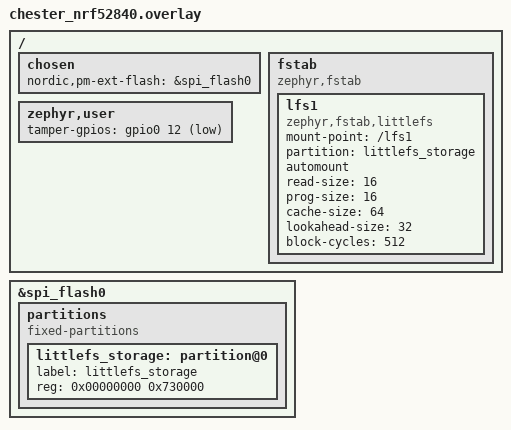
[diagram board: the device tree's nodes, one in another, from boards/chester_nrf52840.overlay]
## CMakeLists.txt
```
#
# Copyright (c) 2023 HARDWARIO a.s.
#
# SPDX-License-Identifier: LicenseRef-HARDWARIO-5-Clause
#

cmake_minimum_required(VERSION 3.20.0)

set(SHIELD ctr_k1 ctr_lte_v2 ctr_ds18b20 ctr_z)
set(ENV{FW_BUNDLE} "com.hardwario.chester.app.batterycheck.current")
set(ENV{FW_VERSION} "v2.1.0")
set(ENV{FW_NAME} "CHESTER BatteryCheck")

find_package(Zephyr REQUIRED HINTS $ENV{ZEPHYR_BASE})
project(app)

add_custom_command(
  COMMAND west gen-codec -d ../codec/cbor-decoder.yaml -e ../codec/cbor-encoder.yaml -o ../src/app_codec.h
  OUTPUT ../src/app_codec.h
  DEPENDS ../codec/cbor-decoder.yaml ../codec/cbor-encoder.yaml
)

target_sources(app PRIVATE src/app_cbor.c)
target_sources(app PRIVATE src/app_config.c)

target_sources(app PRIVATE src/app_backup.c)
target_sources(app PRIVATE src/app_tamper.c)
target_sources(app PRIVATE src/app_data.c)
target_sources(app PRIVATE src/app_handler.c)
target_sources(app PRIVATE src/app_init.c)
target_sources(app PRIVATE src/app_power.c)
target_sources(app PRIVATE src/app_sensor.c)
target_sources(app PRIVATE src/app_shell.c)
target_sources(app PRIVATE src/app_work.c)

target_sources(app PRIVATE src/main.c)

target_sources(app PRIVATE src/app_codec.h)
```

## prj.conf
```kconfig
#
# Copyright (c) 2023 HARDWARIO a.s.
#
# SPDX-License-Identifier: LicenseRef-HARDWARIO-5-Clause
#

CONFIG_ADC_NRFX_SAADC=n
CONFIG_ADC_SHELL=n

CONFIG_CTR_ACCEL=y
CONFIG_CTR_BATT=y

CONFIG_CTR_BUTTON=y
CONFIG_APP_TAMPER=y
CONFIG_CTR_BLE=n

CONFIG_CTR_BUF=y
CONFIG_CTR_CLOUD=y
CONFIG_CTR_DEFAULTS=y
CONFIG_CTR_INFO=y
CONFIG_CTR_LED=y
CONFIG_CTR_LOG=y
CONFIG_CTR_RTC=y
CONFIG_CTR_SHELL=y
CONFIG_CTR_THERM=y
CONFIG_CTR_WDOG=y
CONFIG_NEWLIB_LIBC_NANO=n
CONFIG_TINYCRYPT=y
CONFIG_TINYCRYPT_SHA256=y
CONFIG_ZCBOR=y
CONFIG_ZCBOR_STOP_ON_ERROR=y
CONFIG_ENTROPY_GENERATOR=y
CONFIG_SETTINGS_SHELL=y
CONFIG_IMG_MANAGER=y
CONFIG_BOOTLOADER_MCUBOOT=y
CONFIG_CTR_LTE_V2_GNSS=y
CONFIG_CTR_GNSS=y

# CONFIG_MCUBOOT_EXTRA_IMGTOOL_ARGS="--custom-tlv 0xff00 tralala"

CONFIG_PM_PARTITION_SIZE_SETTINGS_STORAGE=0x8000
CONFIG_PM_OVERRIDE_EXTERNAL_DRIVER_CHECK=y
CONFIG_SPI=y

CONFIG_DFU_TARGET=y
CONFIG_DFU_TARGET_STREAM=y
CONFIG_DFU_TARGET_MCUBOOT=y
CONFIG_DFU_TARGET_LOG_LEVEL_DBG=y

CONFIG_STREAM_FLASH_ERASE=y
CONFIG_STREAM_FLASH=y

# CONFIG_CTR_LTE_LINK_LOG_LEVEL_DBG=y
# CONFIG_CTR_LTE_LINK_LOG_LEVEL_INF=y
# CONFIG_CTR_LTE_LINK_LOG_LEVEL_ERR=y

CONFIG_CTR_LTE_V2_LOG_LEVEL_DBG=y
# CONFIG_CTR_LTE_V2_LOG_LEVEL_ERR=y

CONFIG_CTR_K1_LOG_LEVEL_DBG=y
# CONFIG_CTR_K1_LOG_LEVEL_ERR=y

CONFIG_ADC_TLA2021_INIT_PRIORITY=60


# Enable file system support
CONFIG_FILE_SYSTEM=y
CONFIG_FILE_SYSTEM_LITTLEFS=y
CONFIG_FILE_SYSTEM_MKFS=y
CONFIG_FILE_SYSTEM_SHELL=y
# CONFIG_FILE_SYSTEM_SHELL_TEST_COMMANDS=y
CONFIG_SETTINGS_FILE=y
CONFIG_SETTINGS_FILE_PATH="/lfs1/settings/run"
# Use external flash for littlefs file system
CONFIG_PM_PARTITION_REGION_LITTLEFS_EXTERNAL=y
```

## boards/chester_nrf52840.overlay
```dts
/*
 * Copyright (c) 2023 HARDWARIO a.s.
 *
 * SPDX-License-Identifier: LicenseRef-HARDWARIO-5-Clause
 */

/ {
	chosen {
		nordic,pm-ext-flash = &spi_flash0;
	};
};

&spi_flash0 {
	partitions {
		compatible = "fixed-partitions";
		#address-cells = <1>;
		#size-cells = <1>;

		littlefs_storage: partition@0 {
			label = "littlefs_storage";

			/*
			 * This size doesn't matter due to Nordic's partition
			 * manager; For the sake of consistency this should
			 * match the configured size
			 */
			reg = <0x00000000 0x730000>;
		};
	};
};

/ {
	fstab {
		compatible = "zephyr,fstab";
		lfs1: lfs1 {
			compatible = "zephyr,fstab,littlefs";
			mount-point = "/lfs1";
			partition = <&littlefs_storage>;
			automount;
			read-size = <16>;
			prog-size = <16>;
			cache-size = <64>;
			lookahead-size = <32>;
			block-cycles = <512>;
		};
	};
};

/ {
	zephyr,user {
		tamper-gpios = <&gpio0 12 GPIO_ACTIVE_LOW>;
	};
};
```

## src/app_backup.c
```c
#include "app_backup.h"
#include "app_data.h"
#include "app_work.h"

/* CHESTER includes */
#include <chester/drivers/ctr_z.h>

/* Zephyr includes */
#include <zephyr/device.h>
#include <zephyr/devicetree.h>
#include <zephyr/kernel.h>
#include <zephyr/logging/log.h>

/* Standard includes */
#include <errno.h>
#include <math.h>
#include <stdbool.h>

LOG_MODULE_REGISTER(app_backup, LOG_LEVEL_DBG);

#if defined(CONFIG_SHIELD_CTR_Z)

int app_backup_sample(void)
{
	int ret;

	static const struct device *dev = DEVICE_DT_GET(DT_NODELABEL(ctr_z));

	if (!device_is_ready(dev)) {
		LOG_ERR("Device not ready");
		ret = -ENODEV;
		goto error;
	}

	struct ctr_z_status status;
	ret = ctr_z_get_status(dev, &status);
	if (ret) {
		LOG_ERR("Call `ctr_z_get_status` failed: %d", ret);
		goto error;
	}

	LOG_INF("DC input connected: %d", status.dc_input_connected);

	uint16_t vdc;
	ret = ctr_z_get_vdc_mv(dev, &vdc);
	if (ret) {
		LOG_ERR("Call `ctr_z_get_vdc_mv` failed: %d", ret);
		goto error;
	}

	LOG_INF("Voltage DC input: %u mV", vdc);

	uint16_t vbat;
	ret = ctr_z_get_vbat_mv(dev, &vbat);
	if (ret) {
		LOG_ERR("Call `ctr_z_get_vbat_mv` failed: %d", ret);
		goto error;
	}

	LOG_INF("Voltage backup battery: %u mV", vbat);

	app_data_lock();
	g_app_data.backup.line_present = status.dc_input_connected;
	g_app_data.backup.line_voltage = vdc / 1000.f;
	g_app_data.backup.battery_voltage = vbat / 1000.f;
	app_data_unlock();

	return 0;

error:
	app_data_lock();
	g_app_data.backup.line_present = false;
	g_app_data.backup.line_voltage = NAN;
	g_app_data.backup.battery_voltage = NAN;
	app_data_unlock();

	return ret;
}

int app_backup_clear(void)
{
	app_data_lock();
	g_app_data.backup.event_count = 0;

	for (int i = 0; i < APP_DATA_BUTTON_COUNT; i++) {
		g_app_data.button[i].event_count = 0;
	}
	app_data_unlock();

	return 0;
}

#endif /* defined(CONFIG_SHIELD_CTR_Z) */
```

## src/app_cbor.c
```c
#include "app_cbor.h"
#include "app_data.h"
#include "app_codec.h"

/* CHESTER includes */
#include <chester/ctr_info.h>
#include <chester/ctr_lte_v2.h>
#include <chester/ctr_rtc.h>
#include <chester/ctr_buf.h>
#include <chester/ctr_cloud.h>
#include <chester/drivers/ctr_z.h>

/* Zephyr includes */
#include <zephyr/kernel.h>
#include <zephyr/logging/log.h>

#include <zcbor_common.h>
#include <zcbor_decode.h>
#include <zcbor_encode.h>

/* Standard includes */
#include <errno.h>
#include <math.h>
#include <stdbool.h>
#include <stddef.h>
#include <stdint.h>
#include <stdlib.h>

// #define CONFIG_SHIELD_CTR_Z 1

LOG_MODULE_REGISTER(app_cbor, LOG_LEVEL_DBG);

__unused static void put_sample_mul(zcbor_state_t *zs, struct app_data_analog_aggreg *sample,
				    float mul)
{
	if (isnan(sample->min)) {
		zcbor_nil_put(zs, NULL);
	} else {
		zcbor_int32_put(zs, sample->min * mul);
	}

	if (isnan(sample->max)) {
		zcbor_nil_put(zs, NULL);
	} else {
		zcbor_int32_put(zs, sample->max * mul);
	}

	if (isnan(sample->avg)) {
		zcbor_nil_put(zs, NULL);
	} else {
		zcbor_int32_put(zs, sample->avg * mul);
	}

	if (isnan(sample->mdn)) {
		zcbor_nil_put(zs, NULL);
	} else {
		zcbor_int32_put(zs, sample->mdn * mul);
	}
}

__unused static void put_sample(zcbor_state_t *zs, struct app_data_analog_aggreg *sample)
{
	put_sample_mul(zs, sample, 1.f);
}

int encode(zcbor_state_t *zs)
{
	int ret;

	zs->constant_state->stop_on_error = true;

	zcbor_map_start_encode(zs, ZCBOR_VALUE_IS_INDEFINITE_LENGTH);

	zcbor_uint32_put(zs, CODEC_KEY_E_MESSAGE);
	{
		zcbor_map_start_encode(zs, ZCBOR_VALUE_IS_INDEFINITE_LENGTH);

		zcbor_uint32_put(zs, CODEC_KEY_E_MESSAGE__SEQUENCE);
		zcbor_uint32_put(zs, g_app_data.sequence++);

		uint64_t timestamp;
		ret = ctr_rtc_get_ts(&timestamp);
		if (ret) {
			LOG_ERR("Call `ctr_rtc_get_ts` failed: %d", ret);
			return ret;
		}

		zcbor_uint32_put(zs, CODEC_KEY_E_MESSAGE__TIMESTAMP);
		zcbor_uint64_put(zs, timestamp);

		zcbor_map_end_encode(zs, ZCBOR_VALUE_IS_INDEFINITE_LENGTH);
	}

	zcbor_uint32_put(zs, CODEC_KEY_E_SYSTEM);
	{
		zcbor_map_start_encode(zs, ZCBOR_VALUE_IS_INDEFINITE_LENGTH);

		zcbor_uint32_put(zs, CODEC_KEY_E_SYSTEM__UPTIME);
		zcbor_uint64_put(zs, k_uptime_get() / 1000);

		zcbor_uint32_put(zs, CODEC_KEY_E_SYSTEM__VOLTAGE_REST);
		if (isnan(g_app_data.system_voltage_rest)) {
			zcbor_nil_put(zs, NULL);
		} else {
			zcbor_uint32_put(zs, g_app_data.system_voltage_rest);
		}

		zcbor_uint32_put(zs, CODEC_KEY_E_SYSTEM__VOLTAGE_LOAD);
		if (isnan(g_app_data.system_voltage_load)) {
			zcbor_nil_put(zs, NULL);
		} else {
			zcbor_uint32_put(zs, g_app_data.system_voltage_load);
		}

		zcbor_uint32_put(zs, CODEC_KEY_E_SYSTEM__CURRENT_LOAD);
		if (isnan(g_app_data.system_current_load)) {
			zcbor_nil_put(zs, NULL);
		} else {
			zcbor_uint32_put(zs, g_app_data.system_current_load);
		}

		char *serial_number;
		ctr_info_get_serial_number(&serial_number);

		zcbor_uint32_put(zs, CODEC_KEY_E_SYSTEM__SERIAL_NUMBER);
		zcbor_tstr_put_term(zs, serial_number);

		zcbor_map_end_encode(zs, ZCBOR_VALUE_IS_INDEFINITE_LENGTH);
	}

	zcbor_uint32_put(zs, CODEC_KEY_E_NETWORK);
	{
		zcbor_map_start_encode(zs, ZCBOR_VALUE_IS_INDEFINITE_LENGTH);

		zcbor_uint32_put(zs, CODEC_KEY_E_NETWORK__PARAMETER);
		{
			zcbor_map_start_encode(zs, ZCBOR_VALUE_IS_INDEFINITE_LENGTH);

			static struct ctr_lte_v2_conn_param conn_param;
			ret = ctr_lte_v2_get_conn_param(&conn_param);
			if (ret) {
				LOG_ERR("Call `ctr_lte_v2_state_get_conn_param` failed: %d", ret);
				return ret;
			}

			zcbor_uint32_put(zs, CODEC_KEY_E_NETWORK__PARAMETER__EEST);
			if (conn_param.valid) {
				zcbor_int32_put(zs, conn_param.eest);
			} else {
				zcbor_nil_put(zs, NULL);
			}

			zcbor_uint32_put(zs, CODEC_KEY_E_NETWORK__PARAMETER__ECL);
			if (conn_param.valid) {
				zcbor_int32_put(zs, conn_param.ecl);
			} else {
				zcbor_nil_put(zs, NULL);
			}

			zcbor_uint32_put(zs, CODEC_KEY_E_NETWORK__PARAMETER__RSRP);
			if (conn_param.valid) {
				zcbor_int32_put(zs, conn_param.rsrp);
			} else {
				zcbor_nil_put(zs, NULL);
			}

			zcbor_uint32_put(zs, CODEC_KEY_E_NETWORK__PARAMETER__RSRQ);
			if (conn_param.valid) {
				zcbor_int32_put(zs, conn_param.rsrq);
			} else {
				zcbor_nil_put(zs, NULL);
			}

			zcbor_uint32_put(zs, CODEC_KEY_E_NETWORK__PARAMETER__SNR);
			if (conn_param.valid) {
				zcbor_int32_put(zs, conn_param.snr);
			} else {
				zcbor_nil_put(zs, NULL);
			}

			zcbor_uint32_put(zs, CODEC_KEY_E_NETWORK__PARAMETER__PLMN);
			if (conn_param.valid) {
				zcbor_int32_put(zs, conn_param.plmn);
			} else {
				zcbor_nil_put(zs, NULL);
			}

			zcbor_uint32_put(zs, CODEC_KEY_E_NETWORK__PARAMETER__CID);
			if (conn_param.valid) {
				zcbor_int32_put(zs, conn_param.cid);
			} else {
				zcbor_nil_put(zs, NULL);
			}

			zcbor_uint32_put(zs, CODEC_KEY_E_NETWORK__PARAMETER__BAND);
			if (conn_param.valid) {
				zcbor_int32_put(zs, conn_param.band);
			} else {
				zcbor_nil_put(zs, NULL);
			}

			zcbor_uint32_put(zs, CODEC_KEY_E_NETWORK__PARAMETER__EARFCN);
			if (conn_param.valid) {
				zcbor_int32_put(zs, conn_param.earfcn);
			} else {
				zcbor_nil_put(zs, NULL);
			}

			zcbor_map_end_encode(zs, ZCBOR_VALUE_IS_INDEFINITE_LENGTH);
		}

		zcbor_map_end_encode(zs, ZCBOR_VALUE_IS_INDEFINITE_LENGTH);
	}

	zcbor_uint32_put(zs, CODEC_KEY_E_THERMOMETER);
	{
		zcbor_map_start_encode(zs, ZCBOR_VALUE_IS_INDEFINITE_LENGTH);

		zcbor_uint32_put(zs, CODEC_KEY_E_THERMOMETER__TEMPERATURE);
		if (isnan(g_app_data.therm_temperature)) {
			zcbor_nil_put(zs, NULL);
		} else {
			zcbor_int32_put(zs, g_app_data.therm_temperature * 100.f);
		}

		zcbor_map_end_encode(zs, ZCBOR_VALUE_IS_INDEFINITE_LENGTH);
	}

	zcbor_uint32_put(zs, CODEC_KEY_E_ACCELEROMETER);
	{
		zcbor_map_start_encode(zs, ZCBOR_VALUE_IS_INDEFINITE_LENGTH);

		zcbor_uint32_put(zs, CODEC_KEY_E_ACCELEROMETER__ACCELERATION_X);
		if (isnan(g_app_data.accel_acceleration_x)) {
			zcbor_nil_put(zs, NULL);
		} else {
			zcbor_int32_put(zs, g_app_data.accel_acceleration_x * 1000.f);
		}

		zcbor_uint32_put(zs, CODEC_KEY_E_ACCELEROMETER__ACCELERATION_Y);
		if (isnan(g_app_data.accel_acceleration_y)) {
			zcbor_nil_put(zs, NULL);
		} else {
			zcbor_int32_put(zs, g_app_data.accel_acceleration_y * 1000.f);
		}

		zcbor_uint32_put(zs, CODEC_KEY_E_ACCELEROMETER__ACCELERATION_Z);
		if (isnan(g_app_data.accel_acceleration_z)) {
			zcbor_nil_put(zs, NULL);
		} else {
			zcbor_int32_put(zs, g_app_data.accel_acceleration_z * 1000.f);
		}

		zcbor_uint32_put(zs, CODEC_KEY_E_ACCELEROMETER__ORIENTATION);
		if (g_app_data.accel_orientation == INT_MAX) {
			zcbor_nil_put(zs, NULL);
		} else {
			zcbor_uint32_put(zs, g_app_data.accel_orientation);
		}

		zcbor_map_end_encode(zs, ZCBOR_VALUE_IS_INDEFINITE_LENGTH);
	}

	zcbor_uint32_put(zs, CODEC_KEY_E_BUFFER);
	{
		zcbor_list_start_encode(zs, ZCBOR_VALUE_IS_INDEFINITE_LENGTH);

		for (int i = 0; i < 5; i++) {
			zcbor_int32_put(zs, 1000000 + i);
		}

		zcbor_list_end_encode(zs, ZCBOR_VALUE_IS_INDEFINITE_LENGTH);
	}

	encode_custom(zs);

	zcbor_map_end_encode(zs, ZCBOR_VALUE_IS_INDEFINITE_LENGTH);

	if (!zcbor_check_error(zs)) {
		LOG_ERR("Encoding failed: %d", zcbor_pop_error(zs));
		return -EFAULT;
	}

	return 0;
}

void encode_custom(zcbor_state_t *zs){

#if defined(CONFIG_SHIELD_CTR_Z)
	zcbor_uint32_put(zs, CODEC_KEY_E_CUSTOM__BACKUP);
	{
		zcbor_map_start_encode(zs, ZCBOR_VALUE_IS_INDEFINITE_LENGTH);

		zcbor_uint32_put(zs, CODEC_KEY_E_CUSTOM__LINE_VOLTAGE);
		if (isnan(g_app_data.backup.line_voltage)) {
			zcbor_nil_put(zs, NULL);
		} else {
			zcbor_int32_put(zs, g_app_data.backup.line_voltage * 1000.f);
		}

		zcbor_uint32_put(zs, CODEC_KEY_E_CUSTOM__BATT_VOLTAGE);
		if (isnan(g_app_data.backup.battery_voltage)) {
			zcbor_nil_put(zs, NULL);
		} else {
			zcbor_int32_put(zs, g_app_data.backup.battery_voltage * 1000.f);
		}

		zcbor_uint32_put(zs, CODEC_KEY_E_CUSTOM__BACKUP_STATE);
		zcbor_uint32_put(zs, g_app_data.backup.line_present ? 1 : 0);

		if (g_app_data.backup.event_count) {
			int64_t timestamp_abs = g_app_data.backup.events[0].timestamp;

			zcbor_uint32_put(zs, CODEC_KEY_E_CUSTOM__BACKUP_EVENTS);
			{
				zcbor_list_start_encode(zs, ZCBOR_VALUE_IS_INDEFINITE_LENGTH);

				/* TSO absolute timestamp */
				zcbor_int64_put(zs, timestamp_abs);

				for (int i = 0; i < g_app_data.backup.event_count; i++) {
					/* TSO offset timestamp */
					zcbor_int64_put(zs, g_app_data.backup.events[i].timestamp -
								    timestamp_abs);
					zcbor_uint32_put(
						zs, g_app_data.backup.events[i].connected ? 1 : 0);
				}

				zcbor_list_end_encode(zs, ZCBOR_VALUE_IS_INDEFINITE_LENGTH);
			}
		} else {
			zcbor_uint32_put(zs, CODEC_KEY_E_CUSTOM__BACKUP_EVENTS);
			{
				zcbor_list_start_encode(zs, ZCBOR_VALUE_IS_INDEFINITE_LENGTH);
				zcbor_list_end_encode(zs, ZCBOR_VALUE_IS_INDEFINITE_LENGTH);
			}
		}

		zcbor_map_end_encode(zs, ZCBOR_VALUE_IS_INDEFINITE_LENGTH);
	}
#endif /* defined(CONFIG_SHIELD_CTR_Z) */

#if defined(CONFIG_SHIELD_CTR_K1)
	zcbor_uint32_put(zs, CODEC_KEY_E_CUSTOM__ANALOG_CHANNELS);
	{
		zcbor_list_start_encode(zs, ZCBOR_VALUE_IS_INDEFINITE_LENGTH);
		for (int i = 0; i < APP_CONFIG_CHANNEL_COUNT; i++) {

			if (!g_app_config.channel_active[i]) {
				continue;
			}

			zcbor_map_start_encode(zs, ZCBOR_VALUE_IS_INDEFINITE_LENGTH);

			zcbor_uint32_put(zs, CODEC_KEY_E_CUSTOM__CHANNEL);
			zcbor_uint64_put(zs, i + 1);

			zcbor_uint32_put(zs, CODEC_KEY_E_CUSTOM__MEASUREMENTS_ANALOG_CHANNELS);
			{
				zcbor_list_start_encode(zs, ZCBOR_VALUE_IS_INDEFINITE_LENGTH);

				struct app_data_channel *ch = &g_app_data.channel[i];
				zcbor_uint64_put(zs, ch->timestamp);
				zcbor_uint32_put(zs, g_app_config.channel_interval_aggreg);

				for (int j = 0; j < g_app_data.channel[i].measurement_count; j++) {
					put_sample(zs, &ch->measurements_mean[j]);
					// put_sample(zs, &ch->measurements_rms[j]);
				}

				zcbor_list_end_encode(zs, ZCBOR_VALUE_IS_INDEFINITE_LENGTH);
			}

			zcbor_map_end_encode(zs, ZCBOR_VALUE_IS_INDEFINITE_LENGTH);
		}
		zcbor_list_end_encode(zs, ZCBOR_VALUE_IS_INDEFINITE_LENGTH);
	}
#endif /* defined(CONFIG_SHIELD_CTR_K1) */

#if defined(CONFIG_APP_TAMPER)
	zcbor_uint32_put(zs, CODEC_KEY_E_CUSTOM__BUTTONS);
	{
		zcbor_list_start_encode(zs, ZCBOR_VALUE_IS_INDEFINITE_LENGTH);
		for (int i = 0; i < APP_DATA_BUTTON_COUNT; i++) {

			struct app_data_button *ch = &g_app_data.button[i];

			zcbor_map_start_encode(zs, ZCBOR_VALUE_IS_INDEFINITE_LENGTH);

			zcbor_uint32_put(zs, CODEC_KEY_E_CUSTOM__BUTTON);
			zcbor_uint64_put(zs, i + 1);

			zcbor_uint32_put(zs, CODEC_KEY_E_CUSTOM__BUTTON_EVENTS);
			{
				zcbor_list_start_encode(zs, ZCBOR_VALUE_IS_INDEFINITE_LENGTH);

				zcbor_uint64_put(zs, ch->timestamp);
				zcbor_uint32_put(zs, g_app_config.channel_interval_aggreg);

				for (int j = 0; j < g_app_data.button[i].event_count; j++) {
					zcbor_int32_put(zs, ch->events[j].open);
					zcbor_int32_put(zs, ch->events[j].close);
				}

				zcbor_list_end_encode(zs, ZCBOR_VALUE_IS_INDEFINITE_LENGTH);
			}

			zcbor_map_end_encode(zs, ZCBOR_VALUE_IS_INDEFINITE_LENGTH);
		}
		zcbor_list_end_encode(zs, ZCBOR_VALUE_IS_INDEFINITE_LENGTH);
	}
#endif /* defined(CONFIG_APP_TAMPER) */

#if defined(CONFIG_SHIELD_CTR_DS18B20)
	zcbor_uint32_put(zs, CODEC_KEY_E_CUSTOM__W1_THERMOMETERS);
	{
		zcbor_list_start_encode(zs, ZCBOR_VALUE_IS_INDEFINITE_LENGTH);
		for (int i = 0; i < APP_DATA_W1_THERM_COUNT; i++) {
			struct app_data_w1_therm_sensor *sensor = &g_app_data.w1_therm.sensor[i];

			if (!sensor->serial_number) {
				continue;
			}

			zcbor_map_start_encode(zs, ZCBOR_VALUE_IS_INDEFINITE_LENGTH);

			zcbor_uint32_put(zs, CODEC_KEY_E_CUSTOM__SERIAL_NUMBER);
			zcbor_uint64_put(zs, sensor->serial_number);

			zcbor_uint32_put(zs, CODEC_KEY_E_CUSTOM__W1_THERMOMETERS__MEASUREMENTS_DIV);
			{
				zcbor_list_start_encode(zs, ZCBOR_VALUE_IS_INDEFINITE_LENGTH);

				zcbor_uint64_put(zs, g_app_data.w1_therm.timestamp);
				zcbor_uint32_put(zs, g_app_config.w1_therm_interval_aggreg);

				for (int j = 0; j < sensor->measurement_count; j++) {
					put_sample_mul(zs, &sensor->measurements[j].temperature,
						       100.f);
				}

				zcbor_list_end_encode(zs, ZCBOR_VALUE_IS_INDEFINITE_LENGTH);
			}

			zcbor_map_end_encode(zs, ZCBOR_VALUE_IS_INDEFINITE_LENGTH);
		}
		zcbor_list_end_encode(zs, ZCBOR_VALUE_IS_INDEFINITE_LENGTH);
	}
#endif /* defined(CONFIG_SHIELD_CTR_DS18B20) */

}

int decode(zcbor_state_t *zs, struct app_cbor_received *received)
{
	memset(received, 0, sizeof(struct app_cbor_received));

	if (!zcbor_map_start_decode(zs)) {
		return -EBADMSG;
	}

	uint32_t key;
	bool ok;

	while (1) {
		if (!zcbor_uint32_decode(zs, &key)) {
			break;
		}

		switch (key) {
		case CODEC_KEY_D_LED_R:
			ok = zcbor_int32_decode(zs, &received->led_r);
			received->has_led_r = true;
			break;
		case CODEC_KEY_D_LED_G:
			ok = zcbor_int32_decode(zs, &received->led_g);
			received->has_led_g = true;
			break;
		case CODEC_KEY_D_LED_Y:
			ok = zcbor_int32_decode(zs, &received->led_y);
			received->has_led_y = true;
			break;
		case CODEC_KEY_D_LED_LOAD:
			ok = zcbor_int32_decode(zs, &received->led_load);
			received->has_led_load = true;
			break;
		}
		if (!ok) {
			LOG_ERR("Encoding failed: %d", zcbor_peek_error(zs));
			return -EBADMSG;
		}
	}

	if (!zcbor_map_end_decode(zs)) {
		return -EBADMSG;
	}

	return 0;
}

int app_cbor_encode(zcbor_state_t *zs)
{
	int ret;

	app_data_lock();

	ret = encode(zs);
	if (ret) {
		LOG_ERR("Call `encode` failed: %d", ret);
		app_data_unlock();
		return ret;
	}

	app_data_unlock();

	return 0;
}

int app_cbor_decode(zcbor_state_t *zs, struct app_cbor_received *received)
{
	int ret;
	ret = decode(zs, received);
	if (ret) {
		LOG_ERR("Call `decode` failed: %d", ret);
		return ret;
	}

	return 0;
}
```

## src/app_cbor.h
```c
#ifndef APP_CBOR_H_
#define APP_CBOR_H_

/* Zephyr includes */
#include <zephyr/kernel.h>

#include <zcbor_common.h>

#ifdef __cplusplus
extern "C" {
#endif

struct app_cbor_received
{
	bool has_led_r;
	int32_t led_r;
	bool has_led_g;
	int32_t led_g;
	bool has_led_y;
	int32_t led_y;
	bool has_led_load;
	int32_t led_load;
};

void encode_custom(zcbor_state_t *zs);
int app_cbor_encode(zcbor_state_t *zs);
int app_cbor_decode(zcbor_state_t *zs, struct app_cbor_received *received);

#ifdef __cplusplus
}
#endif

#endif /* APP_CBOR_H_ */
```

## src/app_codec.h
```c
#ifndef CODEC_H_
#define CODEC_H_

/* This file has been generated using the script gen-codec.py */

#ifdef __cplusplus
extern "C" {
#endif

#define CODEC_CLOUD_DECODER_HASH ((uint64_t)0x2e0696177eab62d9)
#define CODEC_CLOUD_ENCODER_HASH ((uint64_t)0xe074aea1e4183ce4)

enum codec_key_e {
	CODEC_KEY_E_MESSAGE = 0,
	CODEC_KEY_E_MESSAGE__SEQUENCE = 1,
	CODEC_KEY_E_MESSAGE__TIMESTAMP = 2,
	CODEC_KEY_E_SYSTEM = 3,
	CODEC_KEY_E_SYSTEM__SERIAL_NUMBER = 4,
	CODEC_KEY_E_SYSTEM__UPTIME = 5,
	CODEC_KEY_E_SYSTEM__VOLTAGE_REST = 6,
	CODEC_KEY_E_SYSTEM__VOLTAGE_LOAD = 7,
	CODEC_KEY_E_SYSTEM__CURRENT_LOAD = 8,
	CODEC_KEY_E_NETWORK = 9,
	CODEC_KEY_E_NETWORK__PARAMETER = 10,
	CODEC_KEY_E_NETWORK__PARAMETER__EEST = 11,
	CODEC_KEY_E_NETWORK__PARAMETER__ECL = 12,
	CODEC_KEY_E_NETWORK__PARAMETER__RSRP = 13,
	CODEC_KEY_E_NETWORK__PARAMETER__RSRQ = 14,
	CODEC_KEY_E_NETWORK__PARAMETER__SNR = 15,
	CODEC_KEY_E_NETWORK__PARAMETER__PLMN = 16,
	CODEC_KEY_E_NETWORK__PARAMETER__CID = 17,
	CODEC_KEY_E_NETWORK__PARAMETER__BAND = 18,
	CODEC_KEY_E_NETWORK__PARAMETER__EARFCN = 19,
	CODEC_KEY_E_THERMOMETER = 20,
	CODEC_KEY_E_THERMOMETER__TEMPERATURE = 21,
	CODEC_KEY_E_ACCELEROMETER = 22,
	CODEC_KEY_E_ACCELEROMETER__ACCELERATION_X = 23,
	CODEC_KEY_E_ACCELEROMETER__ACCELERATION_Y = 24,
	CODEC_KEY_E_ACCELEROMETER__ACCELERATION_Z = 25,
	CODEC_KEY_E_ACCELEROMETER__ORIENTATION = 26,
	CODEC_KEY_E_BUFFER = 27,
	CODEC_KEY_E_CUSTOM = 28,
	CODEC_KEY_E_CUSTOM__W1_THERMOMETERS = 29,
	CODEC_KEY_E_CUSTOM__W1_THERMOMETERS__MEASUREMENTS_DIV = 30,
	CODEC_KEY_E_CUSTOM__SERIAL_NUMBER = 31,
	CODEC_KEY_E_CUSTOM__CHANNEL = 32,
	CODEC_KEY_E_CUSTOM__ANALOG_CHANNELS = 33,
	CODEC_KEY_E_CUSTOM__MEASUREMENTS_ANALOG_CHANNELS = 34,
	CODEC_KEY_E_CUSTOM__BACKUP_STATE = 35,
	CODEC_KEY_E_CUSTOM__LINE_VOLTAGE = 36,
	CODEC_KEY_E_CUSTOM__BATT_VOLTAGE = 37,
	CODEC_KEY_E_CUSTOM__BACKUP = 38,
	CODEC_KEY_E_CUSTOM__BACKUP_EVENTS = 39,
	CODEC_KEY_E_CUSTOM__BUTTONS = 40,
	CODEC_KEY_E_CUSTOM__BUTTON = 41,
	CODEC_KEY_E_CUSTOM__BUTTON_EVENTS = 42,
	CODEC_KEY_E_CUSTOM__BUTTON_BTN = 43,
	CODEC_KEY_E_CUSTOM__BUTTON_TMP = 44,
	CODEC_KEY_E_CUSTOM__COUNT_OPEN = 45,
	CODEC_KEY_E_CUSTOM__COUNT_CLOSE = 46,
};

enum codec_key_d {
	CODEC_KEY_D_LED_R = 0,
	CODEC_KEY_D_LED_G = 1,
	CODEC_KEY_D_LED_Y = 2,
	CODEC_KEY_D_LED_LOAD = 3,
};

#define CODEC_CLOUD_OPTIONS_STATIC(_name) \
	static const uint8_t _name##_cloud_decoder[] = CLOUD_DECODER_BUFFER; \
	static const uint8_t _name##_cloud_encoder[] = CLOUD_ENCODER_BUFFER; \
	static struct ctr_cloud_options _name = { \
		.decoder_hash = CODEC_CLOUD_DECODER_HASH, \
		.encoder_hash = CODEC_CLOUD_ENCODER_HASH, \
		.decoder_buf = _name##_cloud_decoder, \
		.decoder_len = 1086, \
		.encoder_buf = _name##_cloud_encoder, \
		.encoder_len = 147, \
}

#define CLOUD_DECODER_BUFFER { \
	0xa4, 0x67, 0x76, 0x65, 0x72, 0x73, 0x69, 0x6f, \
	0x6e, 0x02, 0x64, 0x74, 0x79, 0x70, 0x65, 0x67, \
	0x64, 0x65, 0x63, 0x6f, 0x64, 0x65, 0x72, 0x64, \
	0x6e, 0x61, 0x6d, 0x65, 0x78, 0x1e, 0x63, 0x6f, \
	0x6d, 0x2e, 0x68, 0x61, 0x72, 0x64, 0x77, 0x61, \
	0x72, 0x69, 0x6f, 0x2e, 0x63, 0x68, 0x65, 0x73, \
	0x74, 0x65, 0x72, 0x2e, 0x61, 0x70, 0x70, 0x2e, \
	0x64, 0x65, 0x6d, 0x6f, 0x66, 0x73, 0x63, 0x68, \
	0x65, 0x6d, 0x61, 0x87, 0xa1, 0x67, 0x6d, 0x65, \
	0x73, 0x73, 0x61, 0x67, 0x65, 0x82, 0xa1, 0x68, \
	0x73, 0x65, 0x71, 0x75, 0x65, 0x6e, 0x63, 0x65, \
	0xf6, 0xa1, 0x69, 0x74, 0x69, 0x6d, 0x65, 0x73, \
	0x74, 0x61, 0x6d, 0x70, 0xf6, 0xa1, 0x66, 0x73, \
	0x79, 0x73, 0x74, 0x65, 0x6d, 0x85, 0xa1, 0x6d, \
	0x73, 0x65, 0x72, 0x69, 0x61, 0x6c, 0x5f, 0x6e, \
	0x75, 0x6d, 0x62, 0x65, 0x72, 0xf6, 0xa1, 0x66, \
	0x75, 0x70, 0x74, 0x69, 0x6d, 0x65, 0xf6, 0xa1, \
	0x6c, 0x76, 0x6f, 0x6c, 0x74, 0x61, 0x67, 0x65, \
	0x5f, 0x72, 0x65, 0x73, 0x74, 0x82, 0xa1, 0x64, \
	0x24, 0x64, 0x69, 0x76, 0x19, 0x03, 0xe8, 0xa1, \
	0x64, 0x24, 0x66, 0x70, 0x70, 0x02, 0xa1, 0x6c, \
	0x76, 0x6f, 0x6c, 0x74, 0x61, 0x67, 0x65, 0x5f, \
	0x6c, 0x6f, 0x61, 0x64, 0x82, 0xa1, 0x64, 0x24, \
	0x64, 0x69, 0x76, 0x19, 0x03, 0xe8, 0xa1, 0x64, \
	0x24, 0x66, 0x70, 0x70, 0x02, 0xa1, 0x6c, 0x63, \
	0x75, 0x72, 0x72, 0x65, 0x6e, 0x74, 0x5f, 0x6c, \
	0x6f, 0x61, 0x64, 0xf6, 0xa1, 0x67, 0x6e, 0x65, \
	0x74, 0x77, 0x6f, 0x72, 0x6b, 0x81, 0xa1, 0x69, \
	0x70, 0x61, 0x72, 0x61, 0x6d, 0x65, 0x74, 0x65, \
	0x72, 0x89, 0xa1, 0x64, 0x65, 0x65, 0x73, 0x74, \
	0xf6, 0xa1, 0x63, 0x65, 0x63, 0x6c, 0xf6, 0xa1, \
	0x64, 0x72, 0x73, 0x72, 0x70, 0xf6, 0xa1, 0x64, \
	0x72, 0x73, 0x72, 0x71, 0xf6, 0xa1, 0x63, 0x73, \
	0x6e, 0x72, 0xf6, 0xa1, 0x64, 0x70, 0x6c, 0x6d, \
	0x6e, 0xf6, 0xa1, 0x63, 0x63, 0x69, 0x64, 0xf6, \
	0xa1, 0x64, 0x62, 0x61, 0x6e, 0x64, 0xf6, 0xa1, \
	0x66, 0x65, 0x61, 0x72, 0x66, 0x63, 0x6e, 0xf6, \
	0xa1, 0x6b, 0x74, 0x68, 0x65, 0x72, 0x6d, 0x6f, \
	0x6d, 0x65, 0x74, 0x65, 0x72, 0x81, 0xa1, 0x6b, \
	0x74, 0x65, 0x6d, 0x70, 0x65, 0x72, 0x61, 0x74, \
	0x75, 0x72, 0x65, 0x82, 0xa1, 0x64, 0x24, 0x64, \
	0x69, 0x76, 0x18, 0x64, 0xa1, 0x64, 0x24, 0x66, \
	0x70, 0x70, 0x02, 0xa1, 0x6d, 0x61, 0x63, 0x63, \
	0x65, 0x6c, 0x65, 0x72, 0x6f, 0x6d, 0x65, 0x74, \
	0x65, 0x72, 0x84, 0xa1, 0x6e, 0x61, 0x63, 0x63, \
	0x65, 0x6c, 0x65, 0x72, 0x61, 0x74, 0x69, 0x6f, \
	0x6e, 0x5f, 0x78, 0x82, 0xa1, 0x64, 0x24, 0x64, \
	0x69, 0x76, 0x19, 0x03, 0xe8, 0xa1, 0x64, 0x24, \
	0x66, 0x70, 0x70, 0x02, 0xa1, 0x6e, 0x61, 0x63, \
	0x63, 0x65, 0x6c, 0x65, 0x72, 0x61, 0x74, 0x69, \
	0x6f, 0x6e, 0x5f, 0x79, 0x82, 0xa1, 0x64, 0x24, \
	0x64, 0x69, 0x76, 0x19, 0x03, 0xe8, 0xa1, 0x64, \
	0x24, 0x66, 0x70, 0x70, 0x02, 0xa1, 0x6e, 0x61, \
	0x63, 0x63, 0x65, 0x6c, 0x65, 0x72, 0x61, 0x74, \
	0x69, 0x6f, 0x6e, 0x5f, 0x7a, 0x82, 0xa1, 0x64, \
	0x24, 0x64, 0x69, 0x76, 0x19, 0x03, 0xe8, 0xa1, \
	0x64, 0x24, 0x66, 0x70, 0x70, 0x02, 0xa1, 0x6b, \
	0x6f, 0x72, 0x69, 0x65, 0x6e, 0x74, 0x61, 0x74, \
	0x69, 0x6f, 0x6e, 0xf6, 0xa1, 0x66, 0x62, 0x75, \
	0x66, 0x66, 0x65, 0x72, 0xf6, 0xa1, 0x66, 0x63, \
	0x75, 0x73, 0x74, 0x6f, 0x6d, 0x91, 0xa1, 0x6f, \
	0x77, 0x31, 0x5f, 0x74, 0x68, 0x65, 0x72, 0x6d, \
	0x6f, 0x6d, 0x65, 0x74, 0x65, 0x72, 0x73, 0x81, \
	0xa1, 0x70, 0x6d, 0x65, 0x61, 0x73, 0x75, 0x72, \
	0x65, 0x6d, 0x65, 0x6e, 0x74, 0x73, 0x5f, 0x64, \
	0x69, 0x76, 0x81, 0xa1, 0x64, 0x24, 0x74, 0x73, \
	0x70, 0x84, 0xa1, 0x63, 0x6d, 0x69, 0x6e, 0x82, \
	0xa1, 0x64, 0x24, 0x64, 0x69, 0x76, 0x18, 0x64, \
	0xa1, 0x64, 0x24, 0x66, 0x70, 0x70, 0x02, 0xa1, \
	0x63, 0x6d, 0x61, 0x78, 0x82, 0xa1, 0x64, 0x24, \
	0x64, 0x69, 0x76, 0x18, 0x64, 0xa1, 0x64, 0x24, \
	0x66, 0x70, 0x70, 0x02, 0xa1, 0x63, 0x61, 0x76, \
	0x67, 0x82, 0xa1, 0x64, 0x24, 0x64, 0x69, 0x76, \
	0x18, 0x64, 0xa1, 0x64, 0x24, 0x66, 0x70, 0x70, \
	0x02, 0xa1, 0x63, 0x6d, 0x64, 0x6e, 0x82, 0xa1, \
	0x64, 0x24, 0x64, 0x69, 0x76, 0x18, 0x64, 0xa1, \
	0x64, 0x24, 0x66, 0x70, 0x70, 0x02, 0xa1, 0x6d, \
	0x73, 0x65, 0x72, 0x69, 0x61, 0x6c, 0x5f, 0x6e, \
	0x75, 0x6d, 0x62, 0x65, 0x72, 0xf6, 0xa1, 0x67, \
	0x63, 0x68, 0x61, 0x6e, 0x6e, 0x65, 0x6c, 0xf6, \
	0xa1, 0x6f, 0x61, 0x6e, 0x61, 0x6c, 0x6f, 0x67, \
	0x5f, 0x63, 0x68, 0x61, 0x6e, 0x6e, 0x65, 0x6c, \
	0x73, 0xf6, 0xa1, 0x78, 0x1c, 0x6d, 0x65, 0x61, \
	0x73, 0x75, 0x72, 0x65, 0x6d, 0x65, 0x6e, 0x74, \
	0x73, 0x5f, 0x61, 0x6e, 0x61, 0x6c, 0x6f, 0x67, \
	0x5f, 0x63, 0x68, 0x61, 0x6e, 0x6e, 0x65, 0x6c, \
	0x73, 0x81, 0xa1, 0x64, 0x24, 0x74, 0x73, 0x70, \
	0x84, 0xa1, 0x68, 0x6d, 0x65, 0x61, 0x6e, 0x5f, \
	0x6d, 0x69, 0x6e, 0x82, 0xa1, 0x64, 0x24, 0x64, \
	0x69, 0x76, 0x19, 0x03, 0xe8, 0xa1, 0x64, 0x24, \
	0x66, 0x70, 0x70, 0x03, 0xa1, 0x68, 0x6d, 0x65, \
	0x61, 0x6e, 0x5f, 0x6d, 0x61, 0x78, 0x82, 0xa1, \
	0x64, 0x24, 0x64, 0x69, 0x76, 0x19, 0x03, 0xe8, \
	0xa1, 0x64, 0x24, 0x66, 0x70, 0x70, 0x03, 0xa1, \
	0x68, 0x6d, 0x65, 0x61, 0x6e, 0x5f, 0x61, 0x76, \
	0x67, 0x82, 0xa1, 0x64, 0x24, 0x64, 0x69, 0x76, \
	0x19, 0x03, 0xe8, 0xa1, 0x64, 0x24, 0x66, 0x70, \
	0x70, 0x03, 0xa1, 0x68, 0x6d, 0x65, 0x61, 0x6e, \
	0x5f, 0x6d, 0x64, 0x6e, 0x82, 0xa1, 0x64, 0x24, \
	0x64, 0x69, 0x76, 0x19, 0x03, 0xe8, 0xa1, 0x64, \
	0x24, 0x66, 0x70, 0x70, 0x03, 0xa1, 0x6c, 0x62, \
	0x61, 0x63, 0x6b, 0x75, 0x70, 0x5f, 0x73, 0x74, \
	0x61, 0x74, 0x65, 0x81, 0xa1, 0x65, 0x24, 0x65, \
	0x6e, 0x75, 0x6d, 0x82, 0x68, 0x69, 0x6e, 0x61, \
	0x63, 0x74, 0x69, 0x76, 0x65, 0x66, 0x61, 0x63, \
	0x74, 0x69, 0x76, 0x65, 0xa1, 0x6c, 0x6c, 0x69, \
	0x6e, 0x65, 0x5f, 0x76, 0x6f, 0x6c, 0x74, 0x61, \
	0x67, 0x65, 0x82, 0xa1, 0x64, 0x24, 0x64, 0x69, \
	0x76, 0x19, 0x03, 0xe8, 0xa1, 0x64, 0x24, 0x66, \
	0x70, 0x70, 0x02, 0xa1, 0x6c, 0x62, 0x61, 0x74, \
	0x74, 0x5f, 0x76, 0x6f, 0x6c, 0x74, 0x61, 0x67, \
	0x65, 0x82, 0xa1, 0x64, 0x24, 0x64, 0x69, 0x76, \
	0x19, 0x03, 0xe8, 0xa1, 0x64, 0x24, 0x66, 0x70, \
	0x70, 0x02, 0xa1, 0x66, 0x62, 0x61, 0x63, 0x6b, \
	0x75, 0x70, 0xf6, 0xa1, 0x6d, 0x62, 0x61, 0x63, \
	0x6b, 0x75, 0x70, 0x5f, 0x65, 0x76, 0x65, 0x6e, \
	0x74, 0x73, 0x81, 0xa1, 0x64, 0x24, 0x74, 0x73, \
	0x70, 0x81, 0xa1, 0x64, 0x74, 0x79, 0x70, 0x65, \
	0x81, 0xa1, 0x65, 0x24, 0x65, 0x6e, 0x75, 0x6d, \
	0x82, 0x6c, 0x64, 0x69, 0x73, 0x63, 0x6f, 0x6e, \
	0x6e, 0x65, 0x63, 0x74, 0x65, 0x64, 0x69, 0x63, \
	0x6f, 0x6e, 0x6e, 0x65, 0x63, 0x74, 0x65, 0x64, \
	0xa1, 0x67, 0x62, 0x75, 0x74, 0x74, 0x6f, 0x6e, \
	0x73, 0xf6, 0xa1, 0x66, 0x62, 0x75, 0x74, 0x74, \
	0x6f, 0x6e, 0xf6, 0xa1, 0x6d, 0x62, 0x75, 0x74, \
	0x74, 0x6f, 0x6e, 0x5f, 0x65, 0x76, 0x65, 0x6e, \
	0x74, 0x73, 0x81, 0xa1, 0x64, 0x24, 0x74, 0x73, \
	0x70, 0x82, 0xa1, 0x64, 0x6f, 0x70, 0x65, 0x6e, \
	0xf6, 0xa1, 0x65, 0x63, 0x6c, 0x6f, 0x73, 0x65, \
	0xf6, 0xa1, 0x6a, 0x62, 0x75, 0x74, 0x74, 0x6f, \
	0x6e, 0x5f, 0x62, 0x74, 0x6e, 0xf6, 0xa1, 0x6a, \
	0x62, 0x75, 0x74, 0x74, 0x6f, 0x6e, 0x5f, 0x74, \
	0x6d, 0x70, 0xf6, 0xa1, 0x6a, 0x63, 0x6f, 0x75, \
	0x6e, 0x74, 0x5f, 0x6f, 0x70, 0x65, 0x6e, 0xf6, \
	0xa1, 0x6b, 0x63, 0x6f, 0x75, 0x6e, 0x74, 0x5f, \
	0x63, 0x6c, 0x6f, 0x73, 0x65, 0xf6, \
}

#define CLOUD_ENCODER_BUFFER { \
	0xa4, 0x67, 0x76, 0x65, 0x72, 0x73, 0x69, 0x6f, \
	0x6e, 0x02, 0x64, 0x74, 0x79, 0x70, 0x65, 0x67, \
	0x65, 0x6e, 0x63, 0x6f, 0x64, 0x65, 0x72, 0x64, \
	0x6e, 0x61, 0x6d, 0x65, 0x78, 0x1e, 0x63, 0x6f, \
	0x6d, 0x2e, 0x68, 0x61, 0x72, 0x64, 0x77, 0x61, \
	0x72, 0x69, 0x6f, 0x2e, 0x63, 0x68, 0x65, 0x73, \
	0x74, 0x65, 0x72, 0x2e, 0x61, 0x70, 0x70, 0x2e, \
	0x64, 0x65, 0x6d, 0x6f, 0x66, 0x73, 0x63, 0x68, \
	0x65, 0x6d, 0x61, 0x84, 0xa1, 0x65, 0x6c, 0x65, \
	0x64, 0x5f, 0x72, 0x81, 0xa1, 0x65, 0x24, 0x74, \
	0x79, 0x70, 0x65, 0x63, 0x69, 0x6e, 0x74, 0xa1, \
	0x65, 0x6c, 0x65, 0x64, 0x5f, 0x67, 0x81, 0xa1, \
	0x65, 0x24, 0x74, 0x79, 0x70, 0x65, 0x63, 0x69, \
	0x6e, 0x74, 0xa1, 0x65, 0x6c, 0x65, 0x64, 0x5f, \
	0x79, 0x81, 0xa1, 0x65, 0x24, 0x74, 0x79, 0x70, \
	0x65, 0x63, 0x69, 0x6e, 0x74, 0xa1, 0x68, 0x6c, \
	0x65, 0x64, 0x5f, 0x6c, 0x6f, 0x61, 0x64, 0x81, \
	0xa1, 0x65, 0x24, 0x74, 0x79, 0x70, 0x65, 0x63, \
	0x69, 0x6e, 0x74, \
}

#ifdef __cplusplus
}
#endif

#endif /* CODEC_H_ */
```

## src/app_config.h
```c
/*
 * Copyright (c) 2023 HARDWARIO a.s.
 *
 * SPDX-License-Identifier: LicenseRef-HARDWARIO-5-Clause
 */

#ifndef APP_CONFIG_H_
#define APP_CONFIG_H_

/* Zephyr includes */
#include <zephyr/shell/shell.h>

/* Standard includes */
#include <stdbool.h>
#include <stddef.h>

#ifdef __cplusplus
extern "C" {
#endif

#define APP_CONFIG_CHANNEL_COUNT 4

#define APP_CONFIG_INTERVAL_REPORT_MIN 30
#define APP_CONFIG_INTERVAL_REPORT_MAX 86400

#if defined(CONFIG_SHIELD_CTR_K1)
int app_config_cmd_config_channel_active(const struct shell *shell, size_t argc, char **argv);
int app_config_cmd_config_channel_differential(const struct shell *shell, size_t argc, char **argv);
int app_config_cmd_config_channel_calib_x0(const struct shell *shell, size_t argc, char **argv);
int app_config_cmd_config_channel_calib_y0(const struct shell *shell, size_t argc, char **argv);
int app_config_cmd_config_channel_calib_x1(const struct shell *shell, size_t argc, char **argv);
int app_config_cmd_config_channel_calib_y1(const struct shell *shell, size_t argc, char **argv);
int h_rev_commit(void);
#endif /* defined(CONFIG_SHIELD_CTR_K1) */

struct app_config {
	int interval_sample;
	int interval_aggreg;
	int interval_report;

#if defined(CONFIG_SHIELD_CTR_Z)
	int event_report_delay;
	int event_report_rate;
	bool backup_report_connected;
	bool backup_report_disconnected;
#endif /* defined(CONFIG_SHIELD_CTR_Z) */

#if defined(CONFIG_SHIELD_CTR_K1)
	int channel_interval_sample;
	int channel_interval_aggreg;
	bool channel_active[APP_CONFIG_CHANNEL_COUNT];
	bool channel_differential[APP_CONFIG_CHANNEL_COUNT];
	int channel_calib_x0[APP_CONFIG_CHANNEL_COUNT];
	int channel_calib_y0[APP_CONFIG_CHANNEL_COUNT];
	int channel_calib_x1[APP_CONFIG_CHANNEL_COUNT];
	int channel_calib_y1[APP_CONFIG_CHANNEL_COUNT];
	int channel_calib_a1;
	int channel_calib_a10;
	int channel_calib_v5;
	int channel_calib_v24;
#endif /* defined(CONFIG_SHIELD_CTR_K1) */

#if defined(CONFIG_SHIELD_CTR_DS18B20)
	int w1_therm_interval_sample;
	int w1_therm_interval_aggreg;
#endif /* defined(CONFIG_SHIELD_CTR_DS18B20) */
};

extern struct app_config g_app_config;

/* clang-format off */

#define CONFIG_PARAM_LIST_COMMON() \
	CONFIG_PARAM_INT(interval-sample, interval_sample, 1, 86400, "Get/Set sample interval in seconds (format: <1-86400>).") \
	CONFIG_PARAM_INT(interval-aggreg, interval_aggreg, 1, 86400, "Get/Set aggregate interval in seconds (format: <1-86400>).") \
	CONFIG_PARAM_INT(interval-report, interval_report, 30, 86400, "Get/Set report interval in seconds (format: <30-86400>).")

#if defined(CONFIG_SHIELD_CTR_Z)
	#define CONFIG_PARAM_LIST_CTR_Z() \
		CONFIG_PARAM_INT(event-report-delay, event_report_delay, 1, 86400, "Get/Set event report delay in seconds (format: <1-86400>).") \
		CONFIG_PARAM_INT(event-report-rate, event_report_rate, 1, 3600, "Get/Set event report rate in reports per hour (format: <1-3600>).") \
		CONFIG_PARAM_BOOL(backup-report-connected, backup_report_connected, "Get/Set report when backup is active (format: true, false).") \
		CONFIG_PARAM_BOOL(backup-report-disconnected, backup_report_disconnected, "Get/Set report when backup is inactive (format: true, false).")
#endif /* defined(CONFIG_SHIELD_CTR_Z) */

#if defined(CONFIG_SHIELD_CTR_K1)
	#define CONFIG_PARAM_LIST_CTR_K1() \
		CONFIG_PARAM_INT(channel-interval-sample, channel_interval_sample, 1, 86400, "Get/Set sample interval in seconds (format: <1-86400>).") \
		CONFIG_PARAM_INT(channel-interval-aggreg, channel_interval_aggreg, 1, 86400, "Get/Set aggregate interval in seconds (format: <1-86400>).") \
		CONFIG_PARAM_INT(channel-calib-a1, channel_calib_a1, 0, 1, "Get/Set channel auto calibration for 1 Amp (format: 0-1).") \
		CONFIG_PARAM_INT(channel-calib-a10, channel_calib_a10, 0, 1, "Get/Set channel auto calibration for 10 Amp (format: 0-1).") \
		CONFIG_PARAM_INT(channel-calib-v5, channel_calib_v5, 0, 1, "Get/Set channel auto calibration for 5 Volt (format: 0-1).") \
		CONFIG_PARAM_INT(channel-calib-v24, channel_calib_v24, 0, 1, "Get/Set channel auto calibration for 24 Volt (format: 0-1).")
#endif /* defined(CONFIG_SHIELD_CTR_K1) */

#if defined(CONFIG_SHIELD_CTR_DS18B20)
	#define CONFIG_PARAM_LIST_CTR_DS18B20() \
		CONFIG_PARAM_INT(w1-therm-interval-sample, w1_therm_interval_sample, 1, 86400, "Get/Set 1-Wire temperature sample interval in seconds (format: <1-86400>).") \
		CONFIG_PARAM_INT(w1-therm-interval-aggreg, w1_therm_interval_aggreg, 1, 86400, "Get/Set 1-Wire temperature aggregate interval in seconds (format: <1-86400>).")
#endif /* defined(CONFIG_SHIELD_CTR_K1) */

/* clang-format on */

#define CONFIG_PARAM_LIST() CONFIG_PARAM_LIST_COMMON()

int app_config_cmd_config_show(const struct shell *shell, size_t argc, char **argv);

#define CONFIG_PARAM_INT(_name_d, _name_u, _min, _max, _help)                                      \
	int app_config_cmd_config_##_name_u(const struct shell *shell, size_t argc, char **argv);
#define CONFIG_PARAM_FLOAT(_name_d, _name_u, _min, _max, _help)                                    \
	int app_config_cmd_config_##_name_u(const struct shell *shell, size_t argc, char **argv);
#define CONFIG_PARAM_BOOL(_name_d, _name_u, _help)                                                 \
	int app_config_cmd_config_##_name_u(const struct shell *shell, size_t argc, char **argv);

CONFIG_PARAM_LIST();

#if defined(CONFIG_PARAM_LIST_CTR_Z)
CONFIG_PARAM_LIST_CTR_Z();
#endif

#if defined(CONFIG_PARAM_LIST_CTR_K1)
CONFIG_PARAM_LIST_CTR_K1();
#endif

#if defined(CONFIG_PARAM_LIST_CTR_DS18B20)
CONFIG_PARAM_LIST_CTR_DS18B20();
#endif

#undef CONFIG_PARAM_INT
#undef CONFIG_PARAM_FLOAT
#undef CONFIG_PARAM_BOOL

#ifdef __cplusplus
}
#endif

#endif /* APP_CONFIG_H_ */
```

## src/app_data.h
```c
/*
 * Copyright (c) 2023 HARDWARIO a.s.
 *
 * SPDX-License-Identifier: LicenseRef-HARDWARIO-5-Clause
 */

#ifndef APP_DATA_H_
#define APP_DATA_H_

#include "app_config.h"

/* CHESTER includes */
#include <chester/ctr_lte.h>

/* Standard includes */
#include <stdbool.h>
#include <stdint.h>

#define APP_DATA_ANALOG_MAX_SAMPLES        32
#define APP_DATA_ANALOG_MAX_MEASUREMENTS   32
#define APP_DATA_MAX_BACKUP_EVENTS         32
#define APP_DATA_MAX_TAMPER_EVENTS         32
#define APP_DATA_W1_THERM_COUNT            10
#define APP_DATA_W1_THERM_MAX_SAMPLES      32
#define APP_DATA_W1_THERM_MAX_MEASUREMENTS 32
#define APP_DATA_BUTTON_COUNT              2
#define APP_DATA_MAX_BUTTON_EVENTS         8

#ifdef __cplusplus
extern "C" {
#endif

#if defined(CONFIG_APP_TAMPER)
struct app_data_tamper_event {
	int64_t timestamp;
	bool activated;
};

struct app_data_tamper {
	bool activated;
	int event_count;
	struct app_data_tamper_event events[APP_DATA_MAX_TAMPER_EVENTS];
};
#endif /* defined(CONFIG_APP_TAMPER) */

#if defined(CONFIG_SHIELD_CTR_Z)
struct app_data_backup_event {
	int64_t timestamp;
	bool connected;
};

struct app_data_backup {
	float line_voltage;
	float battery_voltage;
	bool line_present;
	int event_count;
	struct app_data_backup_event events[APP_DATA_MAX_BACKUP_EVENTS];
};

struct app_data_button_event {
	int open;
	int close;
};

struct app_data_button {
	int64_t timestamp;

	int sample_count;
	int open_count;
	int close_count;

	int event_count;
	struct app_data_button_event events[APP_DATA_MAX_BUTTON_EVENTS];
};
#endif /* defined(CONFIG_SHIELD_CTR_Z) */

#if defined(CONFIG_SHIELD_CTR_K1)
struct app_data_analog_aggreg {
	float min;
	float max;
	float avg;
	float mdn;
};

struct app_data_channel {
	int64_t timestamp;

	int sample_count;
	float samples_mean[APP_DATA_ANALOG_MAX_SAMPLES];
	float samples_rms[APP_DATA_ANALOG_MAX_SAMPLES];

	int measurement_count;
	struct app_data_analog_aggreg measurements_mean[APP_DATA_ANALOG_MAX_MEASUREMENTS];
	struct app_data_analog_aggreg measurements_rms[APP_DATA_ANALOG_MAX_MEASUREMENTS];
};
#endif /* defined(CONFIG_SHIELD_CTR_K1) */

#if defined(CONFIG_SHIELD_CTR_DS18B20)
struct app_data_w1_therm_measurement {
	struct app_data_analog_aggreg temperature;
};

struct app_data_w1_therm_sensor {
	uint64_t serial_number;
	int sample_count;
	float samples_temperature[APP_DATA_W1_THERM_MAX_SAMPLES];

	int measurement_count;
	struct app_data_w1_therm_measurement measurements[APP_DATA_W1_THERM_MAX_MEASUREMENTS];
};

struct app_data_w1_therm {
	struct app_data_w1_therm_sensor sensor[APP_DATA_W1_THERM_COUNT];

	int64_t timestamp;
	atomic_t sample;
	atomic_t aggreg;
};
#endif /* defined(CONFIG_SHIELD_CTR_DS18B20) */

struct app_data {
	uint32_t sequence;
	float system_voltage_rest;
	float system_voltage_load;
	float system_current_load;
	float therm_temperature;
	float accel_acceleration_x;
	float accel_acceleration_y;
	float accel_acceleration_z;
	int accel_orientation;
	int serial_number;

#if defined(CONFIG_APP_TAMPER)
	struct app_data_tamper tamper;
#endif /* defined(CONFIG_APP_TAMPER) */

#if defined(CONFIG_SHIELD_CTR_Z)
	struct app_data_backup backup;
	struct app_data_button button[APP_DATA_BUTTON_COUNT];
#endif /* defined(CONFIG_SHIELD_CTR_Z) */

#if defined(CONFIG_SHIELD_CTR_K1)
	struct app_data_channel channel[4];
#endif /* defined(CONFIG_SHIELD_CTR_K1) */

#if defined(CONFIG_SHIELD_CTR_DS18B20)
	struct app_data_w1_therm w1_therm;
#endif /* defined(CONFIG_SHIELD_CTR_DS18B20) */
};

extern struct app_data g_app_data;

void app_data_lock(void);
void app_data_unlock(void);

#ifdef __cplusplus
}
#endif

#endif /* APP_DATA_H_ */
```

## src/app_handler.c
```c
/*
 * Copyright (c) 2023 HARDWARIO a.s.
 *
 * SPDX-License-Identifier: LicenseRef-HARDWARIO-5-Clause
 */

#include "app_handler.h"
#include "app_config.h"
#include "app_data.h"
#include "app_init.h"
#include "app_work.h"
#include "app_cbor.h"

/* CHESTER includes */
#include <chester/ctr_button.h>
#include <chester/ctr_led.h>
#include <chester/ctr_lrw.h>
#include <chester/ctr_lte.h>
#include <chester/ctr_rtc.h>
#include <chester/drivers/ctr_z.h>

/* Zephyr includes */
#include <zephyr/kernel.h>
#include <zephyr/logging/log.h>
#include <zephyr/sys/reboot.h>

#include <zcbor_common.h>
#include <zcbor_decode.h>
#include <zcbor_encode.h>

/* Standard includes */
#include <math.h>
#include <stdbool.h>
#include <stddef.h>

LOG_MODULE_REGISTER(app_handler, LOG_LEVEL_DBG);


static void app_load_timer_handler(struct k_timer *timer)
{
	ctr_led_set(CTR_LED_CHANNEL_LOAD, 0);
}

K_TIMER_DEFINE(app_load_timer, app_load_timer_handler, NULL);

void app_handler_ctr_button(enum ctr_button_channel chan, enum ctr_button_event ev, int val,
			    void *user_data)
{
	int ret;

	if (chan != CTR_BUTTON_CHANNEL_INT)
		return;

	if (ev == CTR_BUTTON_EVENT_CLICK) {
		for (int i = 0; i < val; i++) {
			ret = ctr_led_set(CTR_LED_CHANNEL_Y, true);
			if (ret) {
				LOG_ERR("Call `ctr_led_set` failed: %d", ret);
				return;
			}

			k_sleep(K_MSEC(50));
			ret = ctr_led_set(CTR_LED_CHANNEL_Y, false);
			if (ret) {
				LOG_ERR("Call `ctr_led_set` failed: %d", ret);
				return;
			}

			k_sleep(K_MSEC(200));
		}

		switch (val) {
		case 1:
			app_work_send();
			break;
		case 2:
			app_work_sample();
			break;
		case 3:
			app_work_sample();
			app_work_aggreg();
			app_work_send();
			break;
		case 4:
			sys_reboot(SYS_REBOOT_COLD);
			break;
		case 5:
			ret = ctr_led_set(CTR_LED_CHANNEL_LOAD, 1);
			if (ret) {
				LOG_ERR("Call `ctr_led_set` failed: %d", ret);
				return;
			}
			k_timer_start(&app_load_timer, K_MINUTES(2), K_FOREVER);
			break;
		}
	}
}

void app_handler_cloud_event(enum ctr_cloud_event event, union ctr_cloud_event_data *data, void *param)
{
	int ret;

	if (event == CTR_CLOUD_EVENT_RECV) {
		LOG_HEXDUMP_INF(data->recv.buf, data->recv.len, "Received:");

		if (data->recv.len < 8) {
			LOG_ERR("Missing encoder hash");
			return;
		}

		uint8_t *buf = (uint8_t *)data->recv.buf + 8;
		size_t len = data->recv.len - 8;

		ZCBOR_STATE_D(zs, 1, buf, len, 1);

		struct app_cbor_received received;

		ret = app_cbor_decode(zs, &received);
		if (ret) {
			LOG_ERR("Call `app_cbor_decode` failed: %d", ret);
			return;
		}

		if (received.has_led_r) {
			LOG_INF("Set LED R to %d", received.led_r);
			ret = ctr_led_set(CTR_LED_CHANNEL_R, received.led_r);
			if (ret) {
				LOG_ERR("Call `ctr_led_set` failed: %d", ret);
				return;
			}
		}

		if (received.has_led_g) {
			LOG_INF("Set LED G to %d", received.led_g);
			ret = ctr_led_set(CTR_LED_CHANNEL_G, received.led_g);
			if (ret) {
				LOG_ERR("Call `ctr_led_set` failed: %d", ret);
				return;
			}
		}

		if (received.has_led_y) {
			LOG_INF("Set LED Y to %d", received.led_y);
			ret = ctr_led_set(CTR_LED_CHANNEL_Y, received.led_y);
			if (ret) {
				LOG_ERR("Call `ctr_led_set` failed: %d", ret);
				return;
			}
		}

		if (received.has_led_load) {
			LOG_INF("Set LED LOAD to %d", received.led_load);
			ret = ctr_led_set(CTR_LED_CHANNEL_LOAD, received.led_load);
			if (ret) {
				LOG_ERR("Call `ctr_led_set` failed: %d", ret);
				return;
			}
		}
	}
}

#if defined(CONFIG_SHIELD_CTR_Z)

void app_handler_ctr_z(const struct device *dev, enum ctr_z_event backup_event, void *param)
{
	int ret;

	if (backup_event != CTR_Z_EVENT_DC_CONNECTED &&
	    backup_event != CTR_Z_EVENT_DC_DISCONNECTED) {
		return;
	}

	struct app_data_backup *backup = &g_app_data.backup;

	app_work_backup_update();

	app_data_lock();

	backup->line_present = backup_event == CTR_Z_EVENT_DC_CONNECTED;

	if (backup->event_count < APP_DATA_MAX_BACKUP_EVENTS) {
		struct app_data_backup_event *event = &backup->events[backup->event_count];

		ret = ctr_rtc_get_ts(&event->timestamp);
		if (ret) {
			LOG_ERR("Call `ctr_rtc_get_ts` failed: %d", ret);
			app_data_unlock();
			return;
		}

		event->connected = backup->line_present;
		backup->event_count++;

		LOG_INF("Event count: %d", backup->event_count);
	} else {
		LOG_WRN("Measurement full");
		app_data_unlock();
		return;
	}

	LOG_INF("Backup: %d", (int)backup->line_present);

	if (g_app_config.backup_report_connected && backup_event == CTR_Z_EVENT_DC_CONNECTED) {
		app_work_send_with_rate_limit();
	}

	if (g_app_config.backup_report_disconnected &&
	    backup_event == CTR_Z_EVENT_DC_DISCONNECTED) {
		app_work_send_with_rate_limit();
	}

	app_data_unlock();
}
#endif /* defined(CONFIG_SHIELD_CTR_Z) */
```

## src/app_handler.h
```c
/*
 * Copyright (c) 2023 HARDWARIO a.s.
 *
 * SPDX-License-Identifier: LicenseRef-HARDWARIO-5-Clause
 */

#ifndef APP_HANDLER_H_
#define APP_HANDLER_H_

/* CHESTER includes */
#include <chester/ctr_button.h>
#include <chester/ctr_cloud.h>
#include <chester/drivers/ctr_z.h>

#ifdef __cplusplus
extern "C" {
#endif

void app_handler_ctr_button(enum ctr_button_channel chan, enum ctr_button_event ev, int val, void *user_data);
void app_handler_cloud_event(enum ctr_cloud_event event, union ctr_cloud_event_data *data, void *param);

#if defined(CONFIG_SHIELD_CTR_Z)
void app_handler_ctr_z(const struct device *dev, enum ctr_z_event event, void *param);
#endif /* defined(CONFIG_SHIELD_CTR_Z) */

#ifdef __cplusplus
}
#endif

#endif /* APP_HANDLER_H_ */
```

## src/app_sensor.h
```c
/*
 * Copyright (c) 2023 HARDWARIO a.s.
 *
 * SPDX-License-Identifier: LicenseRef-HARDWARIO-5-Clause
 */

#ifndef APP_SENSOR_H_
#define APP_SENSOR_H_

/* Standard includes */
#include <stdint.h>

#ifdef __cplusplus
extern "C" {
#endif

int app_sensor_sample(void);

int app_sensor_analog_sample(void);
int app_sensor_analog_aggreg(void);
int app_sensor_analog_clear(void);

int app_button_aggreg(void);

int app_sensor_w1_therm_sample(void);
int app_sensor_w1_therm_aggreg(void);
int app_sensor_w1_therm_clear(void);

#ifdef __cplusplus
}
#endif

#endif /* APP_SENSOR_H_ */
```
